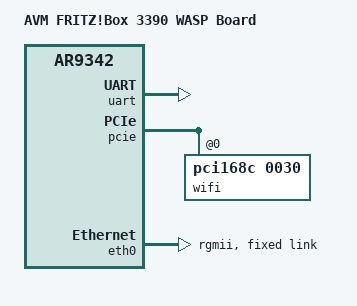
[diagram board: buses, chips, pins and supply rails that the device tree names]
// SPDX-License-Identifier: GPL-2.0-or-later OR MIT
/dts-v1/;

#include <dt-bindings/gpio/gpio.h>
#include <dt-bindings/input/input.h>

#include "ar9344.dtsi"

/ {
	compatible = "avm,fritzbox-3390-wasp", "qca,ar9342";
	model = "AVM FRITZ!Box 3390 WASP Board";
};

&uart {
	status = "okay";
};

&pcie {
	status = "okay";

	wifi@0,0 {
		compatible = "pci168c,0030";
		reg = <0 0 0 0 0>;
		qca,no-eeprom;
	};
};

&eth0 {
	status = "okay";

	phy-mode = "rgmii";

	fixed-link {
		speed = <1000>;
		full-duplex;
	};
};
